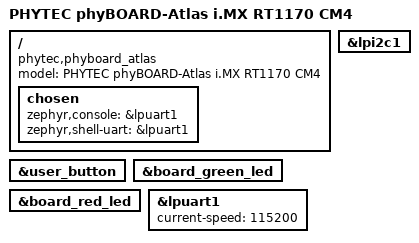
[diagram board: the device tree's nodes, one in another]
/*
 * Copyright 2024, PHYTEC America, LLC
 *
 * SPDX-License-Identifier: Apache-2.0
 */

/dts-v1/;

#include <phytec/phycore_rt1170_mimxrt1176_cm4.dtsi>
#include "phyboard_atlas.dtsi"

/ {
	model = "PHYTEC phyBOARD-Atlas i.MX RT1170 CM4";
	compatible = "phytec,phyboard_atlas";

	chosen {
		zephyr,console = &lpuart1;
		zephyr,shell-uart = &lpuart1;
	};
};

&user_button {
	status = "okay";
};

&board_green_led {
	status = "okay";
};

&board_red_led {
	status = "okay";
};

&lpi2c1 {
	status = "okay";
};

&lpuart1 {
	status = "okay";
	current-speed = <115200>;
};
